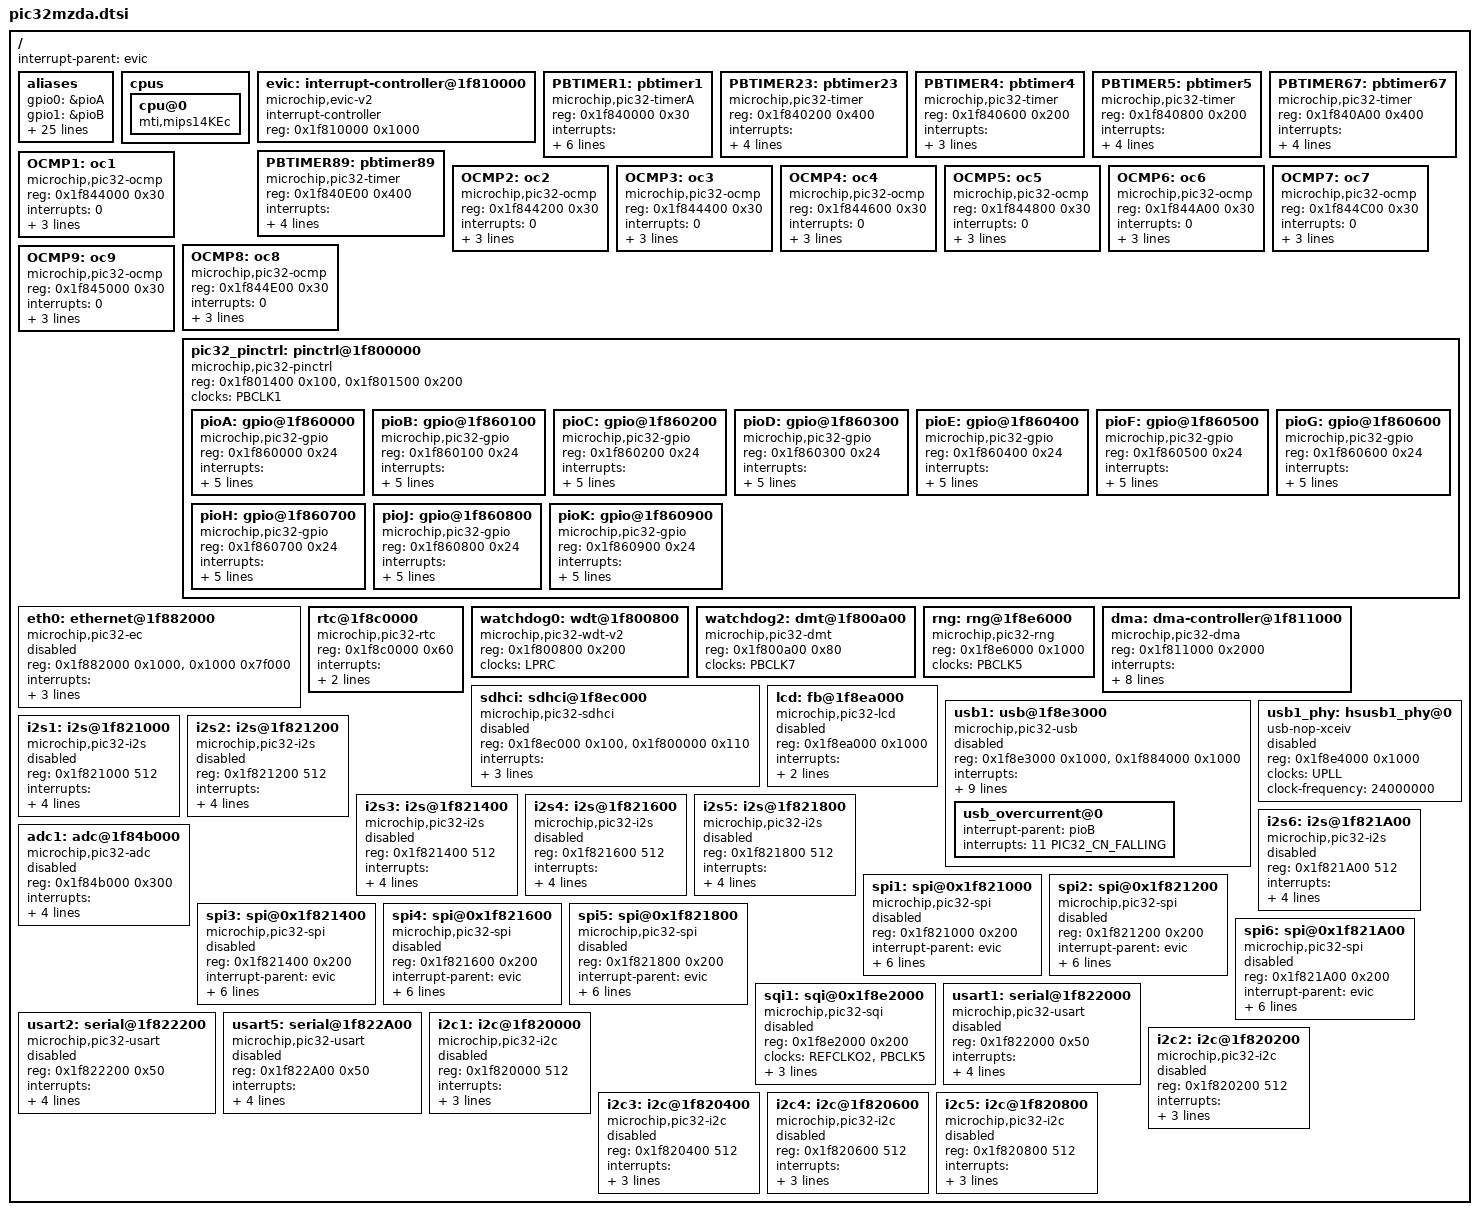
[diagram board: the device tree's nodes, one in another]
/*
 * Copyright 2015 Microchip Technology, Inc.
 *
 * This program is free software; you can redistribute it and/or modify
 * it under the terms of the GNU General Public License version 2 as
 * published by the Free Software Foundation.
 *
 */

#include <dt-bindings/interrupt-controller/microchip,pic32mz-evic.h>

#include "pic32mzda-clk.dtsi"

/ {
	#address-cells = <1>;
	#size-cells = <1>;
	interrupt-parent = <&evic>;

	aliases {
		gpio0 = &pioA;
		gpio1 = &pioB;
		gpio2 = &pioC;
		gpio3 = &pioD;
		gpio4 = &pioE;
		gpio5 = &pioF;
		gpio6 = &pioG;
		gpio7 = &pioH;
		gpio8 = &pioJ;
		gpio9 = &pioK;
		serial1 = &usart2;
		serial5 = &usart5;
		i2s1 = &i2s1;
		i2s2 = &i2s2;
		i2s3 = &i2s3;
		i2s4 = &i2s4;
		i2s5 = &i2s5;
		i2s6 = &i2s6;
		spi1 = &spi1;
		spi2 = &spi2;
		spi3 = &spi3;
		spi4 = &spi4;
		spi5 = &spi5;
		spi6 = &spi6;
		spi7 = &sqi1;
		usb1 = &usb1;
		usb1_phy = &usb1_phy;
	};

	cpus {
		#address-cells = <1>;
		#size-cells = <0>;

		cpu@0 {
			compatible = "mti,mips14KEc";
			device_type = "cpu";
		};
	};

	evic: interrupt-controller@1f810000 {
		compatible = "microchip,evic-v2";
		interrupt-controller;
		#interrupt-cells = <3>;
		reg = <0x1f810000 0x1000>;
		device_type="evic-v2";
	};

	/* 16-bit class-a timer */
	PBTIMER1:pbtimer1 {
		#timer-cells = <0>;
		reg = <0x1f840000 0x30>;
		compatible = "microchip,pic32-timerA";
		interrupts = <TIMER1 DEFAULT_INT_PRI IRQ_TYPE_EDGE_RISING>;
		clocks = <&PBCLK3>, <&SOSC>,/*<&TxCKI>,*/<&LPRC>;
		microchip,clock-indices = <0>, <1>, <5>;
		timer-id = <1>;
		microchip,timer-class-A;  /* class A timer */
		microchip,timer-version = <2>; /* v2 timer */
	};

	/* 32-bit class-b timer */
	PBTIMER23:pbtimer23 {
		#timer-cells = <0>;
		compatible = "microchip,pic32-timer";
		reg = <0x1f840200 0x400>;
		interrupts = <TIMER3 DEFAULT_INT_PRI IRQ_TYPE_EDGE_RISING>;
		clocks = <&PBCLK3>, <&TxCKI>;
		timer-id = <2>;
		microchip,timer-32bit;	 /* class B, 32-bit combined timer */
	};

	/* 16-bit class-b timer */
	PBTIMER4:pbtimer4 {
		#timer-cells = <0>;
		compatible = "microchip,pic32-timer";
		reg = <0x1f840600 0x200>;
		interrupts = <TIMER4 DEFAULT_INT_PRI IRQ_TYPE_EDGE_RISING>;
		clocks = <&PBCLK3>, <&TxCKI>;
		timer-id = <4>;
	};

	/* 16-bit class-b timer */
	PBTIMER5:pbtimer5 {
		#timer-cells = <0>;
		compatible = "microchip,pic32-timer";
		reg = <0x1f840800 0x200>;
		interrupts = <TIMER5 DEFAULT_INT_PRI IRQ_TYPE_EDGE_RISING>;
		clocks = <&PBCLK3>, <&TxCKI>;
		timer-id = <5>;
		microchip,timer-adc; /* can trigger ADC on match */
	};

	/* 32-bit class-b timer */
	PBTIMER67:pbtimer67 {
		#timer-cells = <0>;
		compatible = "microchip,pic32-timer";
		reg = <0x1f840A00 0x400>;
		interrupts = <TIMER7 DEFAULT_INT_PRI IRQ_TYPE_EDGE_RISING>;
		clocks = <&PBCLK3>, <&TxCKI>;
		timer-id = <6>;
		microchip,timer-32bit;
	};

	/* 32-bit class-b timer */
	PBTIMER89:pbtimer89 {
		#timer-cells = <0>;
		compatible = "microchip,pic32-timer";
		reg = <0x1f840E00 0x400>;
		interrupts = <TIMER9 DEFAULT_INT_PRI IRQ_TYPE_EDGE_RISING>;
		clocks = <&PBCLK3>, <&TxCKI>;
		timer-id = <8>;
		microchip,timer-32bit;
	};

	/* 32-bit time-base and 32-bit compare */
	OCMP1:oc1 {
		#oc-cells = <0>;
		compatible = "microchip,pic32-ocmp";
		reg = <0x1f844000 0x30>;
		interrupts = <0>;
		oc-id = <1>;
		microchip,oc-32bit;
		microchip,oc-adc;
	};

	/* 16-bit time-base, hence 16-bit count comparision */
	OCMP2:oc2 {
		#oc-cells = <0>;
		compatible = "microchip,pic32-ocmp";
		reg = <0x1f844200 0x30>;
		interrupts = <0>;
		oc-id = <2>;
		microchip,oc-adc;
		microchip,oc-32bit;
	};

	OCMP3:oc3 {
		#oc-cells = <0>;
		compatible = "microchip,pic32-ocmp";
		reg = <0x1f844400 0x30>;
		interrupts = <0>;
		oc-id = <3>;
		microchip,oc-adc;
		microchip,oc-32bit;
	};

	OCMP4:oc4 {
		#oc-cells = <0>;
		compatible = "microchip,pic32-ocmp";
		reg = <0x1f844600 0x30>;
		interrupts = <0>;
		oc-id = <4>;
		microchip,oc-adc;
		microchip,oc-32bit;
	};

	OCMP5:oc5 {
		#oc-cells = <0>;
		compatible = "microchip,pic32-ocmp";
		reg = <0x1f844800 0x30>;
		interrupts = <0>;
		oc-id = <5>;
		microchip,oc-adc;
		microchip,oc-32bit;
	};

	OCMP6:oc6 {
		#oc-cells = <0>;
		compatible = "microchip,pic32-ocmp";
		reg = <0x1f844A00 0x30>;
		interrupts = <0>;
		oc-id = <2>;
		microchip,oc-adc;
		microchip,oc-32bit;
	};

	OCMP7:oc7 {
		#oc-cells = <0>;
		compatible = "microchip,pic32-ocmp";
		reg = <0x1f844C00 0x30>;
		interrupts = <0>;
		oc-id = <7>;
		microchip,oc-adc;
		microchip,oc-32bit;
	};

	OCMP8:oc8 {
		#oc-cells = <0>;
		compatible = "microchip,pic32-ocmp";
		reg = <0x1f844E00 0x30>;
		interrupts = <0>;
		oc-id = <8>;
		microchip,oc-adc;
		microchip,oc-32bit;
	};

	OCMP9:oc9 {
		#oc-cells = <0>;
		compatible = "microchip,pic32-ocmp";
		reg = <0x1f845000 0x30>;
		interrupts = <0>;
		oc-id = <9>;
		microchip,oc-adc;
		microchip,oc-32bit;
	};

	pic32_pinctrl: pinctrl@1f800000{
		#address-cells = <1>;
		#size-cells = <1>;
		#gpio-range-cells = <3>;
		compatible = "microchip,pic32-pinctrl", "simple-bus";
		ranges;
		reg = <0x1f801400 0x100>, /* in	 */
		      <0x1f801500 0x200>; /* out */
		clocks = <&PBCLK1>;

		/* GPIO banks */
		pioA: gpio@1f860000 {
			compatible = "microchip,pic32-gpio";
			reg = <0x1f860000 0x24>;
			interrupts = <PORTA_INPUT_CHANGE_INTERRUPT
					DEFAULT_INT_PRI IRQ_TYPE_LEVEL_HIGH>;
			#gpio-cells = <2>;
			gpio-controller;
			interrupt-controller;
			#interrupt-cells = <2>;
			gpio-ranges = <&pic32_pinctrl 0 0 32>;
			clocks = <&PBCLK4>;
		};

		pioB: gpio@1f860100 {
			compatible = "microchip,pic32-gpio";
			reg = <0x1f860100 0x24>;
			interrupts = <PORTB_INPUT_CHANGE_INTERRUPT
					DEFAULT_INT_PRI IRQ_TYPE_LEVEL_HIGH>;
			#gpio-cells = <2>;
			gpio-controller;
			interrupt-controller;
			#interrupt-cells = <2>;
			gpio-ranges = <&pic32_pinctrl 0 32 32>;
			clocks = <&PBCLK4>;
		};

		pioC: gpio@1f860200 {
			compatible = "microchip,pic32-gpio";
			reg = <0x1f860200 0x24>;
			interrupts = <PORTC_INPUT_CHANGE_INTERRUPT
					DEFAULT_INT_PRI IRQ_TYPE_LEVEL_HIGH>;
			#gpio-cells = <2>;
			gpio-controller;
			interrupt-controller;
			#interrupt-cells = <2>;
			gpio-ranges = <&pic32_pinctrl 0 64 32>;
			clocks = <&PBCLK4>;
		};

		pioD: gpio@1f860300 {
			compatible = "microchip,pic32-gpio";
			reg = <0x1f860300 0x24>;
			interrupts = <PORTD_INPUT_CHANGE_INTERRUPT
					DEFAULT_INT_PRI IRQ_TYPE_LEVEL_HIGH>;
			#gpio-cells = <2>;
			gpio-controller;
			interrupt-controller;
			#interrupt-cells = <2>;
			gpio-ranges = <&pic32_pinctrl 0 96 32>;
			clocks = <&PBCLK4>;
		};

		pioE: gpio@1f860400 {
			compatible = "microchip,pic32-gpio";
			reg = <0x1f860400 0x24>;
			interrupts = <PORTE_INPUT_CHANGE_INTERRUPT
					DEFAULT_INT_PRI IRQ_TYPE_LEVEL_HIGH>;
			#gpio-cells = <2>;
			gpio-controller;
			interrupt-controller;
			#interrupt-cells = <2>;
			gpio-ranges = <&pic32_pinctrl 0 128 32>;
			clocks = <&PBCLK4>;
		};

		pioF: gpio@1f860500 {
			compatible = "microchip,pic32-gpio";
			reg = <0x1f860500 0x24>;
			interrupts = <PORTF_INPUT_CHANGE_INTERRUPT
					DEFAULT_INT_PRI IRQ_TYPE_LEVEL_HIGH>;
			#gpio-cells = <2>;
			gpio-controller;
			interrupt-controller;
			#interrupt-cells = <2>;
			gpio-ranges = <&pic32_pinctrl 0 160 32>;
			clocks = <&PBCLK4>;
		};

		pioG: gpio@1f860600 {
			compatible = "microchip,pic32-gpio";
			reg = <0x1f860600 0x24>;
			interrupts = <PORTG_INPUT_CHANGE_INTERRUPT
					 DEFAULT_INT_PRI IRQ_TYPE_LEVEL_HIGH>;
			#gpio-cells = <2>;
			gpio-controller;
			interrupt-controller;
			#interrupt-cells = <2>;
			gpio-ranges = <&pic32_pinctrl 0 192 32>;
			clocks = <&PBCLK4>;
		};

		pioH: gpio@1f860700 {
			compatible = "microchip,pic32-gpio";
			reg = <0x1f860700 0x24>;
			interrupts = <PORTH_INPUT_CHANGE_INTERRUPT
					DEFAULT_INT_PRI IRQ_TYPE_LEVEL_HIGH>;
			#gpio-cells = <2>;
			gpio-controller;
			interrupt-controller;
			#interrupt-cells = <2>;
			gpio-ranges = <&pic32_pinctrl 0 224 32>;
			clocks = <&PBCLK4>;
		};

		/* There is no pioI */

		pioJ: gpio@1f860800 {
			compatible = "microchip,pic32-gpio";
			reg = <0x1f860800 0x24>;
			interrupts = <PORTJ_INPUT_CHANGE_INTERRUPT
					DEFAULT_INT_PRI IRQ_TYPE_LEVEL_HIGH>;
			#gpio-cells = <2>;
			gpio-controller;
			interrupt-controller;
			#interrupt-cells = <2>;
			gpio-ranges = <&pic32_pinctrl 0 256 32>;
			clocks = <&PBCLK4>;
		};

		pioK: gpio@1f860900 {
			compatible = "microchip,pic32-gpio";
			reg = <0x1f860900 0x24>;
			interrupts = <PORTK_INPUT_CHANGE_INTERRUPT
					DEFAULT_INT_PRI IRQ_TYPE_LEVEL_HIGH>;
			#gpio-cells = <2>;
			gpio-controller;
			interrupt-controller;
			#interrupt-cells = <2>;
			gpio-ranges = <&pic32_pinctrl 0 288 32>;
			clocks = <&PBCLK4>;
		};
	};

	eth0: ethernet@1f882000 {
		compatible = "microchip,pic32-ec";
		reg = <0x1f882000 0x1000>, <0x1000 0x7f000>;
		reg-names = "regs","mem";
		interrupts = <ETHERNET_INTERRUPT DEFAULT_INT_PRI
				IRQ_TYPE_LEVEL_HIGH>;
		phy-mode = "rmii";
		clock-names = "eth_clk";
		clocks = <&PBCLK5>;
		status = "disabled";
	};

	rtc@1f8c0000 {
		compatible = "microchip,pic32-rtc";
		reg = <0x1f8c0000 0x60>;
		interrupts = <REAL_TIME_CLOCK DEFAULT_INT_PRI
				IRQ_TYPE_EDGE_RISING>;
		clocks = <&PBCLK6>;
	};

	watchdog0: wdt@1f800800 {
		compatible = "microchip,pic32-wdt-v2";
		reg = <0x1f800800 0x200>;
		clocks = <&LPRC>;
	};

	watchdog2: dmt@1f800a00 {
		compatible = "microchip,pic32-dmt";
		reg = <0x1f800a00 0x80>;
		clocks = <&PBCLK7>;
	};

	rng: rng@1f8e6000 {
		compatible = "microchip,pic32-rng";
		reg = <0x1f8e6000 0x1000>;
		clocks = <&PBCLK5>;
	};

	dma: dma-controller@1f811000 {
		compatible = "microchip,pic32-dma";
		reg = <0x1f811000 0x2000>;
		interrupts = <DMA_CHANNEL_0 DEFAULT_INT_PRI
				IRQ_TYPE_EDGE_RISING>,
			<DMA_CHANNEL_1 DEFAULT_INT_PRI IRQ_TYPE_EDGE_RISING>,
			<DMA_CHANNEL_2 DEFAULT_INT_PRI IRQ_TYPE_EDGE_RISING>,
			<DMA_CHANNEL_3 DEFAULT_INT_PRI IRQ_TYPE_EDGE_RISING>,
			<DMA_CHANNEL_4 DEFAULT_INT_PRI IRQ_TYPE_EDGE_RISING>,
			<DMA_CHANNEL_5 DEFAULT_INT_PRI IRQ_TYPE_EDGE_RISING>,
			<DMA_CHANNEL_6 DEFAULT_INT_PRI IRQ_TYPE_EDGE_RISING>,
			<DMA_CHANNEL_7 DEFAULT_INT_PRI IRQ_TYPE_EDGE_RISING>;
		#dma-cells = <1>;
	};

	sdhci: sdhci@1f8ec000 {
		compatible = "microchip,pic32-sdhci";
		reg = <0x1f8ec000 0x100>,
		<0x1f800000 0x110>;
		reg-names = "sdhc", "defconf";
		interrupts = <SDHC_EVENT DEFAULT_INT_PRI IRQ_TYPE_LEVEL_HIGH>;
		clocks = <&REFCLKO4>, <&PBCLK5>;
		clock-names = "base_clk", "sys_clk";
		no-1-8-v;
		status = "disabled";
	};

	lcd: fb@1f8ea000 {
		compatible = "microchip,pic32-lcd";
		reg = <0x1f8ea000 0x1000>;
		interrupts = <GLCD_INTERRUPT DEFAULT_INT_PRI
				IRQ_TYPE_LEVEL_HIGH>;
		clocks = <&REFCLKO5>, <&SYSCLK>;
		clock-names = "lcd_clk", "sys_clk";
		status = "disabled";
	};

	usb1: usb@1f8e3000 {
		compatible = "microchip,pic32-usb";
		reg = <0x1f8e3000 0x1000>,
		      <0x1f884000 0x1000>;
		reg-names = "mc", "control";
		interrupts = <USB_GENERAL_EVENT DEFAULT_INT_PRI
				IRQ_TYPE_EDGE_RISING>,
			<USB_DMA_EVENT DEFAULT_INT_PRI IRQ_TYPE_LEVEL_HIGH>;
		interrupt-names = "mc", "dma", "over_current";
		dr_mode = "host";
		mentor,multipoint = <1>;
		mentor,num-eps = <8>;
		mentor,ram-bits = <11>;
		mentor,power = <500>;
		/*microchip,fifo-mode = <1>;*/
		phys = <&usb1_phy>;
		clocks = <&PBCLK5>;
		clock-names = "usb_clk";
		/*clock-frequency = <24000000>;*/
		status = "disabled";

		usb_overcurrent@0 {
			interrupt-parent = <&pioB>;
			interrupts = <11 PIC32_CN_FALLING>; /* GPIO_B_11 */
		};
	};

	usb1_phy: hsusb1_phy@0 {
		compatible = "usb-nop-xceiv";
		reg = <0x1f8e4000 0x1000>;
		clocks = <&UPLL>;
		clock-names = "main_clk";
		clock-frequency = <24000000>;
		status = "disabled";
	};

	i2s1: i2s@1f821000 {
		compatible = "microchip,pic32-i2s";
		reg = <0x1f821000 512>;
		interrupts = <SPI1_RECEIVE_DONE DEFAULT_INT_PRI
				IRQ_TYPE_LEVEL_HIGH>,
			<SPI1_TRANSFER_DONE DEFAULT_INT_PRI
				IRQ_TYPE_LEVEL_HIGH>;
		dmas = <&dma DMA_CHANNEL_0>,
		<&dma DMA_CHANNEL_1>;
		dma-names = "rx", "tx";
		clocks = <&PBCLK2>, <&REFCLKO1>;
		clock-names = "mck0","mck1";
		status = "disabled";
	};

	i2s2: i2s@1f821200 {
		compatible = "microchip,pic32-i2s";
		reg = <0x1f821200 512>;
		interrupts = <SPI2_RECEIVE_DONE DEFAULT_INT_PRI
				IRQ_TYPE_LEVEL_HIGH>,
			<SPI2_TRANSFER_DONE DEFAULT_INT_PRI
				IRQ_TYPE_LEVEL_HIGH>;
		dmas = <&dma DMA_CHANNEL_2>,
		<&dma DMA_CHANNEL_3>;
		dma-names = "rx", "tx";
		clocks = <&PBCLK2>, <&REFCLKO1>;
		clock-names = "mck0","mck1";
		status = "disabled";
	};

	i2s3: i2s@1f821400 {
		compatible = "microchip,pic32-i2s";
		reg = <0x1f821400 512>;
		interrupts = <SPI3_RECEIVE_DONE DEFAULT_INT_PRI
				IRQ_TYPE_LEVEL_HIGH>,
			<SPI3_TRANSFER_DONE DEFAULT_INT_PRI
				IRQ_TYPE_LEVEL_HIGH>;
		dmas = <&dma DMA_CHANNEL_4>,
		<&dma DMA_CHANNEL_5>;
		dma-names = "rx", "tx";
		clocks = <&PBCLK2>, <&REFCLKO1>;
		clock-names = "mck0","mck1";
		status = "disabled";
	};

	i2s4: i2s@1f821600 {
		compatible = "microchip,pic32-i2s";
		reg = <0x1f821600 512>;
		interrupts = <SPI4_RECEIVE_DONE DEFAULT_INT_PRI
				IRQ_TYPE_LEVEL_HIGH>,
			<SPI4_TRANSFER_DONE DEFAULT_INT_PRI
				IRQ_TYPE_LEVEL_HIGH>;
		dmas = <&dma DMA_CHANNEL_6>,
		<&dma DMA_CHANNEL_7>;
		dma-names = "rx", "tx";
		clocks = <&PBCLK2>, <&REFCLKO1>;
			clock-names = "mck0","mck1";
		status = "disabled";
	};

	i2s5: i2s@1f821800 {
		compatible = "microchip,pic32-i2s";
		reg = <0x1f821800 512>;
		interrupts = <SPI5_RECEIVE_DONE DEFAULT_INT_PRI
				IRQ_TYPE_LEVEL_HIGH>,
			<SPI5_TRANSFER_DONE DEFAULT_INT_PRI
				IRQ_TYPE_LEVEL_HIGH>;
		dmas = <&dma DMA_CHANNEL_0>,
		<&dma DMA_CHANNEL_1>;
		dma-names = "rx", "tx";
		clocks = <&PBCLK2>, <&REFCLKO1>;
		clock-names = "mck0","mck1";
		status = "disabled";
	};

	i2s6: i2s@1f821A00 {
		compatible = "microchip,pic32-i2s";
		reg = <0x1f821A00 512>;
		interrupts = <SPI6_RECEIVE_DONE DEFAULT_INT_PRI
				IRQ_TYPE_LEVEL_HIGH>,
			<SPI6_TRANSFER_DONE DEFAULT_INT_PRI
				IRQ_TYPE_LEVEL_HIGH>;
		dmas = <&dma DMA_CHANNEL_2>,
		<&dma DMA_CHANNEL_3>;
		dma-names = "rx", "tx";
		clocks = <&PBCLK2>, <&REFCLKO1>;
		clock-names = "mck0","mck1";
		status = "disabled";
	};

	adc1: adc@1f84b000 {
		compatible = "microchip,pic32-adc";
		reg = <0x1f84b000 0x300>;
		interrupts = <ADC1_GLOBAL DEFAULT_INT_PRI IRQ_TYPE_LEVEL_HIGH>;
		enabled-channel-mask = <0x10000000>;
		resolution = <12>;
		vref = <3300>;
		status = "disabled";
	};

	spi1:spi@0x1f821000 {
		#address-cells = <1>;
		#size-cells = <0>;
		compatible = "microchip,pic32-spi";
		reg = <0x1f821000 0x200>;
		interrupt-parent = <&evic>;
		interrupts = <SPI1_FAULT DEFAULT_INT_PRI
				IRQ_TYPE_LEVEL_HIGH>,
			<SPI1_RECEIVE_DONE DEFAULT_INT_PRI
				IRQ_TYPE_LEVEL_HIGH>,
			<SPI1_TRANSFER_DONE DEFAULT_INT_PRI
				IRQ_TYPE_LEVEL_HIGH>;
		interrupt-names = "fault","rx","tx";
		clocks = <&PBCLK2>,<&REFCLKO1>;
		clock-names = "mck0","mck1";
		dmas = <&dma DMA_CHANNEL_2>,
			<&dma DMA_CHANNEL_3>;
		dma-names = "spi-rx", "spi-tx";
		status = "disabled";
	};

	spi2:spi@0x1f821200 {
		#address-cells = <1>;
		#size-cells = <0>;
		compatible = "microchip,pic32-spi";
		reg = <0x1f821200 0x200>;
		interrupt-parent = <&evic>;
		interrupts = <SPI2_FAULT DEFAULT_INT_PRI IRQ_TYPE_LEVEL_HIGH>,
			<SPI2_RECEIVE_DONE DEFAULT_INT_PRI
				IRQ_TYPE_LEVEL_HIGH>,
			<SPI2_TRANSFER_DONE DEFAULT_INT_PRI
				IRQ_TYPE_LEVEL_HIGH>;
		interrupt-names = "fault","rx","tx";
		clocks = <&PBCLK2>,<&REFCLKO1>;
		clock-names = "mck0","mck1";
		dmas = <&dma DMA_CHANNEL_2>,
		       <&dma DMA_CHANNEL_3>;
		dma-names = "spi-rx", "spi-tx";
		status = "disabled";
	};

	spi3:spi@0x1f821400 {
		#address-cells = <1>;
		#size-cells = <0>;
		compatible = "microchip,pic32-spi";
		reg = <0x1f821400 0x200>;
		interrupt-parent = <&evic>;
		interrupts = <SPI3_FAULT DEFAULT_INT_PRI IRQ_TYPE_LEVEL_HIGH>,
			<SPI3_RECEIVE_DONE DEFAULT_INT_PRI
				IRQ_TYPE_LEVEL_HIGH>,
			<SPI3_TRANSFER_DONE DEFAULT_INT_PRI
				IRQ_TYPE_LEVEL_HIGH>;
		interrupt-names = "fault","rx","tx";
		clocks = <&PBCLK2>,<&REFCLKO1>;
		clock-names = "mck0","mck1";
		dmas = <&dma DMA_CHANNEL_2>,
		       <&dma DMA_CHANNEL_3>;
		dma-names = "spi-rx", "spi-tx";
		status = "disabled";
	};

	spi4:spi@0x1f821600 {
		#address-cells = <1>;
		#size-cells = <0>;
		compatible = "microchip,pic32-spi";
		reg = <0x1f821600 0x200>;
		interrupt-parent = <&evic>;
		interrupts = <SPI4_FAULT DEFAULT_INT_PRI IRQ_TYPE_LEVEL_HIGH>,
			<SPI4_RECEIVE_DONE DEFAULT_INT_PRI
				IRQ_TYPE_LEVEL_HIGH>,
			<SPI4_TRANSFER_DONE DEFAULT_INT_PRI
				IRQ_TYPE_LEVEL_HIGH>;
		interrupt-names = "fault","rx","tx";
		clocks = <&PBCLK2>,<&REFCLKO1>;
		clock-names = "mck0","mck1";
		dmas = <&dma DMA_CHANNEL_2>,
		       <&dma DMA_CHANNEL_3>;
		dma-names = "spi-rx", "spi-tx";
		status = "disabled";
	};

	spi5:spi@0x1f821800 {
		#address-cells = <1>;
		#size-cells = <0>;
		compatible = "microchip,pic32-spi";
		reg = <0x1f821800 0x200>;
		interrupt-parent = <&evic>;
		interrupts = <SPI5_FAULT DEFAULT_INT_PRI IRQ_TYPE_LEVEL_HIGH>,
			<SPI5_RECEIVE_DONE DEFAULT_INT_PRI
				IRQ_TYPE_LEVEL_HIGH>,
			<SPI5_TRANSFER_DONE DEFAULT_INT_PRI
				IRQ_TYPE_LEVEL_HIGH>;
		interrupt-names = "fault","rx","tx";
		clocks = <&PBCLK2>,<&REFCLKO1>;
		clock-names = "mck0","mck1";
		dmas = <&dma DMA_CHANNEL_2>,
		       <&dma DMA_CHANNEL_3>;
		dma-names = "spi-rx", "spi-tx";
		status = "disabled";
	};

	spi6:spi@0x1f821A00 {
		#address-cells = <1>;
		#size-cells = <0>;
		compatible = "microchip,pic32-spi";
		reg = <0x1f821A00 0x200>;
		interrupt-parent = <&evic>;
		interrupts = <SPI6_FAULT DEFAULT_INT_PRI IRQ_TYPE_LEVEL_HIGH>,
			<SPI6_RECEIVE_DONE DEFAULT_INT_PRI
				IRQ_TYPE_LEVEL_HIGH>,
			<SPI6_TRANSFER_DONE DEFAULT_INT_PRI
				IRQ_TYPE_LEVEL_HIGH>;
		interrupt-names = "fault","rx","tx";
		clocks = <&PBCLK2>,<&REFCLKO1>;
		clock-names = "mck0","mck1";
		dmas = <&dma DMA_CHANNEL_2>,
		       <&dma DMA_CHANNEL_3>;
		dma-names = "spi-rx", "spi-tx";
		status = "disabled";
	};

	sqi1:sqi@0x1f8e2000 {
		#address-cells = <1>;
		#size-cells = <0>;
		compatible = "microchip,pic32-sqi";
		reg = <0x1f8e2000 0x200>;
		clocks = <&REFCLKO2>, <&PBCLK5>;
		clock-names = "spi_ck","reg_ck";
		interrupt-parent = <&evic>;
		interrupts = <SQI1_EVENT DEFAULT_INT_PRI IRQ_TYPE_LEVEL_HIGH>;
		status = "disabled";
	};

	usart1: serial@1f822000 {
		compatible = "microchip,pic32-usart";
		reg = <0x1f822000 0x50>;
		interrupts = <UART1_FAULT DEFAULT_INT_PRI IRQ_TYPE_LEVEL_HIGH>,
			<UART1_RECEIVE_DONE DEFAULT_INT_PRI
				IRQ_TYPE_LEVEL_HIGH>,
			<UART1_TRANSFER_DONE DEFAULT_INT_PRI
				IRQ_TYPE_LEVEL_HIGH>;
		clocks = <&PBCLK2>;
		status = "disabled";
	};

	usart2: serial@1f822200 {
		compatible = "microchip,pic32-usart";
		reg = <0x1f822200 0x50>;
		interrupts = <UART2_FAULT DEFAULT_INT_PRI IRQ_TYPE_LEVEL_HIGH>,
			<UART2_RECEIVE_DONE DEFAULT_INT_PRI
				IRQ_TYPE_LEVEL_HIGH>,
			<UART2_TRANSFER_DONE DEFAULT_INT_PRI
				IRQ_TYPE_LEVEL_HIGH>;
		clocks = <&PBCLK2>;
		status = "disabled";
	};

	usart5: serial@1f822A00 {
		compatible = "microchip,pic32-usart";
		reg = <0x1f822A00 0x50>;
		interrupts = <UART6_FAULT DEFAULT_INT_PRI IRQ_TYPE_LEVEL_HIGH>,
			<UART6_RECEIVE_DONE DEFAULT_INT_PRI
				IRQ_TYPE_LEVEL_HIGH>,
			<UART6_TRANSFER_DONE DEFAULT_INT_PRI
				IRQ_TYPE_LEVEL_HIGH>;
		clocks = <&PBCLK2>;
		status = "disabled";
	};

	i2c1: i2c@1f820000 {
		compatible = "microchip,pic32-i2c";
		reg = <0x1f820000 512>;
		interrupts = <I2C1_MASTER_EVENT DEFAULT_INT_PRI
				IRQ_TYPE_LEVEL_HIGH>;
		clock-frequency = <100000>;
		clocks = <&PBCLK2>;
		status = "disabled";
	};

	i2c2: i2c@1f820200 {
		compatible = "microchip,pic32-i2c";
		reg = <0x1f820200 512>;
		interrupts = <I2C2_MASTER_EVENT DEFAULT_INT_PRI
				IRQ_TYPE_LEVEL_HIGH>;
		clock-frequency = <100000>;
		clocks = <&PBCLK2>;
		status = "disabled";
	};

	i2c3: i2c@1f820400 {
		compatible = "microchip,pic32-i2c";
		reg = <0x1f820400 512>;
		interrupts = <I2C3_MASTER_EVENT DEFAULT_INT_PRI
				IRQ_TYPE_LEVEL_HIGH>;
		clock-frequency = <100000>;
		clocks = <&PBCLK2>;
		status = "disabled";
	};

	i2c4: i2c@1f820600 {
		compatible = "microchip,pic32-i2c";
		reg = <0x1f820600 512>;
		interrupts = <I2C4_MASTER_EVENT DEFAULT_INT_PRI
				IRQ_TYPE_LEVEL_HIGH>;
		clock-frequency = <100000>;
		clocks = <&PBCLK2>;
		status = "disabled";
	};

	i2c5: i2c@1f820800 {
		compatible = "microchip,pic32-i2c";
		reg = <0x1f820800 512>;
		interrupts = <I2C5_MASTER_EVENT DEFAULT_INT_PRI
				IRQ_TYPE_LEVEL_HIGH>;
		clock-frequency = <100000>;
		clocks = <&PBCLK2>;
		status = "disabled";
	};
};
